# APM32L07x register map
File version: 1.0
CPU: CM0+ r0p0, little endian, MPU, no FPU, 4 interrupt priority bits
Registers are 32-bit, read-write, reset 0x0 unless marked. A register's access mark holds for its fields unless they carry their own. Offsets are from the block's base; [hi:lo] are bit positions; 'fields as' and 'values as' point back to an identical list.

## RCM — Reset and clock control
Base 0x40021000
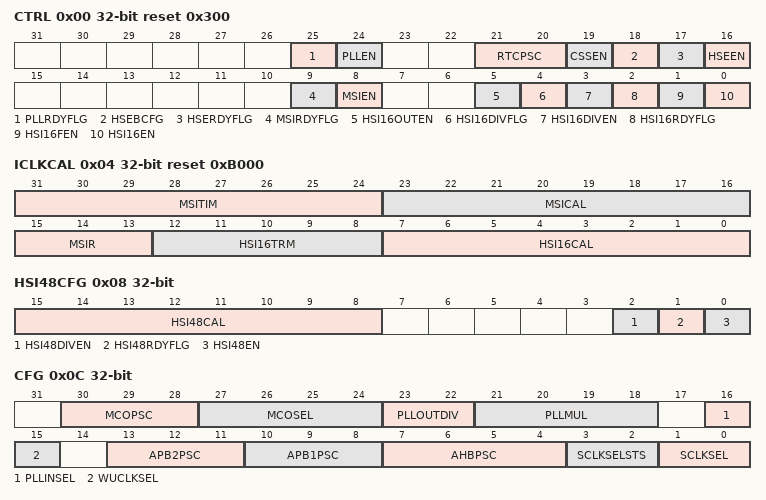
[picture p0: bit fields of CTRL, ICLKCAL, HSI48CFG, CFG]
0x00 CTRL access per field reset 0x300 — Clock control register
  [25] PLLRDYFLG ro — PLL Clock Ready Flag
  [24] PLLEN rw — PLL Enable
  [21:20] RTCPSC rw — RTC Clock Prescaler Factor Configure
  [19] CSSEN rw — Clock Security System Enable
  [18] HSEBCFG rw — High Speed External Clock Bypass Configure
  [17] HSERDYFLG ro — High Speed External Clock Ready Flag
  [16] HSEEN rw — High Speed External Clock Enable
  [9] MSIRDYFLG ro — MSICLK Ready Flag
  [8] MSIEN rw — Multispeed Internal Clock Enable
  [5] HSI16OUTEN rw — HSICLK16 Output Enable
  [4] HSI16DIVFLG ro — 16MHz HSI Divider by 4 Flag
  [3] HSI16DIVEN rw — 16MHz HSI Divider by 4 Enable
  [2] HSI16RDYFLG ro — 16MHz High Speed External Clock Ready Flag
  [1] HSI16FEN rw — 16MHz High Speed Internal Clock Force Enable
  [0] HSI16EN rw — 16MHz High Speed Internal Clock Enable
0x04 ICLKCAL access per field reset 0xB000 — Internal clock sources calibration register
  [31:24] MSITIM rw — MSICLK Trim
  [23:16] MSICAL ro — MSICLK Calibrate
  [15:13] MSIR rw — MSICLK Frequency Range
  [12:8] HSI16TRM rw — HSICLK16 Trim
  [7:0] HSI16CAL ro — HSICLK16 Calibrate
0x08 HSI48CFG access per field — Clock recovery RC register
  [15:8] HSI48CAL ro — HSICLK48 Calibrate
  [2] HSI48DIVEN rw — 48MHz HSI Divider by 6 Enable
  [1] HSI48RDYFLG ro — 48MHz High Speed External Clock Ready Flag
  [0] HSI48EN rw — HSICLK48 Enable
0x0C CFG access per field — Clock configuration register
  [30:28] MCOPSC rw — MCO Clock Output Prescaler Factor Configure
  [27:24] MCOSEL rw — MCO Clock Output Select
  [23:22] PLLOUTDIV rw — PLL Output Clock Divider Factor Configure
  [21:18] PLLMUL rw — PLL Multiplication Factor Configure
  [16] PLLINSEL rw — PLL Input Clock Select
  [15] WUCLKSEL rw — Wake up from STOP Clock Select
  [13:11] APB2PSC rw — APB2 Clock Prescaler Factor Configure
  [10:8] APB1PSC rw — APB1 Clock Prescaler Factor Configure
  [7:4] AHBPSC rw — AHB Clock Prescaler Factor Configure
  [3:2] SCLKSELSTS ro — System Clock Switch Status
  [1:0] SCLKSEL rw — System Clock Source Select
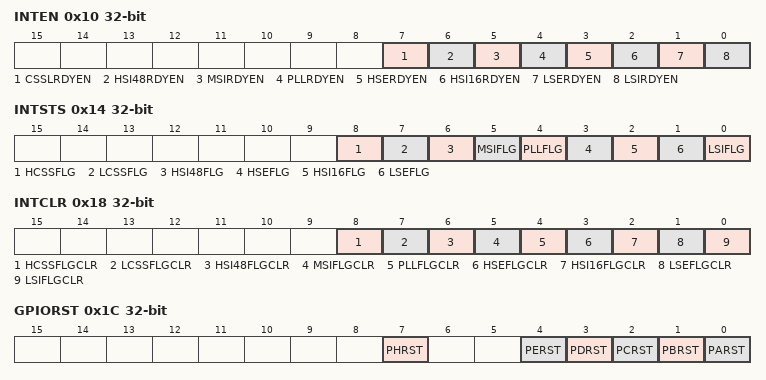
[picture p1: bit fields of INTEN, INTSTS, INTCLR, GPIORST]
0x10 INTEN — Clock interrupt enable register
  [7] CSSLRDYEN — Clock on LSE Security System Interrupt
  [6] HSI48RDYEN — HSICLK48 Ready Interrupt Enable
  [5] MSIRDYEN — MSICLK Ready Interrupt Enable
  [4] PLLRDYEN — PLLCLK Ready Interrupt Enable
  [3] HSERDYEN — HSECLK Ready Interrupt Enable
  [2] HSI16RDYEN — HSICLK16 Ready Interrupt Enable
  [1] LSERDYEN — LSECLK Ready Interrupt Enable
  [0] LSIRDYEN — LSICLK Ready Interrupt Enable
0x14 INTSTS ro — Clock interrupt flag register
  [8] HCSSFLG — HSE Clock Security System Interrupt Flag
  [7] LCSSFLG — LSE Clock Security System Interrupt Flag
  [6] HSI48FLG — HSICLK48 Ready Interrupt Flag
  [5] MSIFLG — MSICLK Ready Interrupt Flag
  [4] PLLFLG — PLLCLK Ready Interrupt Flag
  [3] HSEFLG — HSECLK Ready Interrupt Flag
  [2] HSI16FLG — HSICLK16 Ready Interrupt Flag
  [1] LSEFLG — LSECLK Ready Interrupt Flag
  [0] LSIFLG — LSICLK Ready Interrupt Flag
0x18 INTCLR wo — Clock interrupt clear register
  [8] HCSSFLGCLR — HSE Clock Security System Interrupt Flag Clear
  [7] LCSSFLGCLR — LSE Clock Security System Interrupt Flag Clear
  [6] HSI48FLGCLR — HSICLK48 Ready Interrupt Flag Clear
  [5] MSIFLGCLR — MSICLK Ready Interrupt Flag Clear
  [4] PLLFLGCLR — PLLCLK Ready Interrupt Flag Clear
  [3] HSEFLGCLR — HSECLK Ready Interrupt Flag Clear
  [2] HSI16FLGCLR — HSICLK16 Ready Interrupt Flag Clear
  [1] LSEFLGCLR — LSECLK Ready Interrupt Flag Clear
  [0] LSIFLGCLR — LSICLK Ready Interrupt Flag Clear
0x1C GPIORST — GPIO reset register
  [7] PHRST — GPIOH Reset
  [4] PERST — GPIOE Reset
  [3] PDRST — GPIOD Reset
  [2] PCRST — GPIOC Reset
  [1] PBRST — GPIOB Reset
  [0] PARST — GPIOA Reset
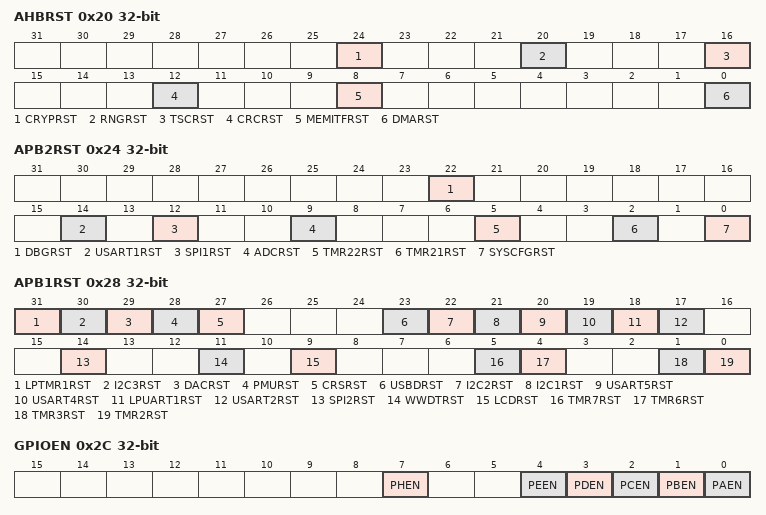
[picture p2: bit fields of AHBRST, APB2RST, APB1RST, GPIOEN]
0x20 AHBRST — AHB peripheral reset register
  [24] CRYPRST — Cryptographic Module Reset
  [20] RNGRST — RNG Reset
  [16] TSCRST — Touch Sensing Controller Module Reset
  [12] CRCRST — CRC Reset
  [8] MEMITFRST — Memory Interface Reset
  [0] DMARST — DMA Reset
0x24 APB2RST — APB2 peripheral reset register
  [22] DBGRST — DBG Reset
  [14] USART1RST — USART1 Reset
  [12] SPI1RST — SPI1 Reset
  [9] ADCRST — ADC Reset
  [5] TMR22RST — TMR22 Reset
  [2] TMR21RST — TMR21 Reset
  [0] SYSCFGRST — SYSCFG Reset
0x28 APB1RST — APB1 peripheral reset register
  [31] LPTMR1RST — LPTMR1 Reset
  [30] I2C3RST — I2C3 Reset
  [29] DACRST — DAC Reset
  [28] PMURST — PMU Reset
  [27] CRSRST — CRS Reset
  [23] USBDRST — USBD Reset
  [22] I2C2RST — I2C2 Reset
  [21] I2C1RST — I2C1 Reset
  [20] USART5RST — USART5 Reset
  [19] USART4RST — USART4 Reset
  [18] LPUART1RST — LPUSART1 Reset
  [17] USART2RST — USART2 Reset
  [14] SPI2RST — SPI2 Reset
  [11] WWDTRST — WWDT Reset
  [9] LCDRST — LCD Reset
  [5] TMR7RST — TMR7 Reset
  [4] TMR6RST — TMR6 Reset
  [1] TMR3RST — TMR3 Reset
  [0] TMR2RST — Timer2 reset
0x2C GPIOEN — GPIO clock enable register
  [7] PHEN — GPIOH Clock Enable
  [4] PEEN — GPIOE Clock Enable
  [3] PDEN — GPIOD Clock Enable
  [2] PCEN — GPIOC Clock Enable
  [1] PBEN — GPIOB Clock Enable
  [0] PAEN — GPIOA Clock Enable
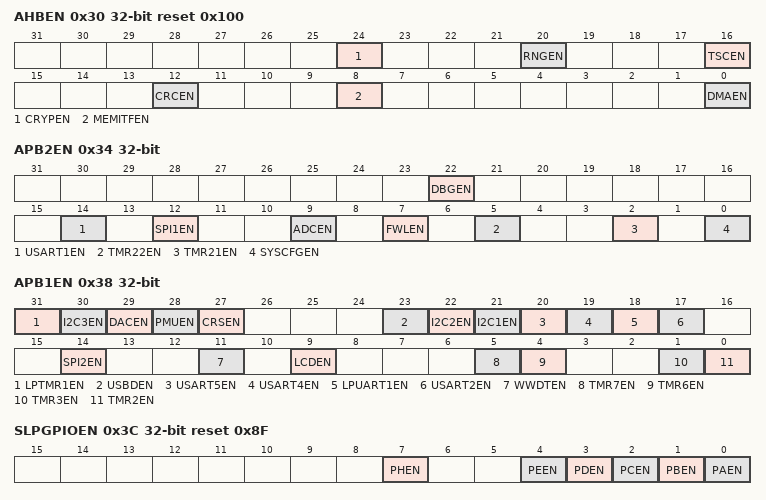
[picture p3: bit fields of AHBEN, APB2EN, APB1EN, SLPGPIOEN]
0x30 AHBEN reset 0x100 — AHB peripheral clock enable register
  [24] CRYPEN — Cryptographic Module Clock Enable
  [20] RNGEN — RNG Clock Enable
  [16] TSCEN — Touch Sensing Controller Module Clock Enable
  [12] CRCEN — CRC Clock Enable
  [8] MEMITFEN — Memory Interface Clock Enable
  [0] DMAEN — DMA Clock Enable
0x34 APB2EN — APB2 peripheral clock enable register
  [22] DBGEN — DBG Clock Enable
  [14] USART1EN — USART1 Clock Enable
  [12] SPI1EN — SPI1 Clock Enable
  [9] ADCEN — ADC Clock Enable
  [7] FWLEN — Firewall Clock Enable
  [5] TMR22EN — TMR22 Clock Enable
  [2] TMR21EN — TMR21 Clock Enable
  [0] SYSCFGEN — SYSCFG Clock Enable
0x38 APB1EN — APB1 peripheral clock enable register
  [31] LPTMR1EN — LPTMR1 Clock Enable
  [30] I2C3EN — I2C3 Clock Enable
  [29] DACEN — DAC Clock Enable
  [28] PMUEN — PMU Clock Enable
  [27] CRSEN — CRS Clock Enable
  [23] USBDEN — USBD Clock Enable
  [22] I2C2EN — I2C2 Clock Enable
  [21] I2C1EN — I2C1 Clock Enable
  [20] USART5EN — USART5 Clock Enable
  [19] USART4EN — USART4 Clock Enable
  [18] LPUART1EN — LPUSART1 Clock Enable
  [17] USART2EN — USART2 Clock Enable
  [14] SPI2EN — SPI2 Clock Enable
  [11] WWDTEN — WWDT Clock Enable
  [9] LCDEN — LCD Clock Enable
  [5] TMR7EN — TMR7 Clock Enable
  [4] TMR6EN — TMR6 Clock Enable
  [1] TMR3EN — TMR3 Clock Enable
  [0] TMR2EN — TMR2 Clock Enable
0x3C SLPGPIOEN reset 0x8F — GPIO clock enable in sleep mode register
  fields as GPIOEN
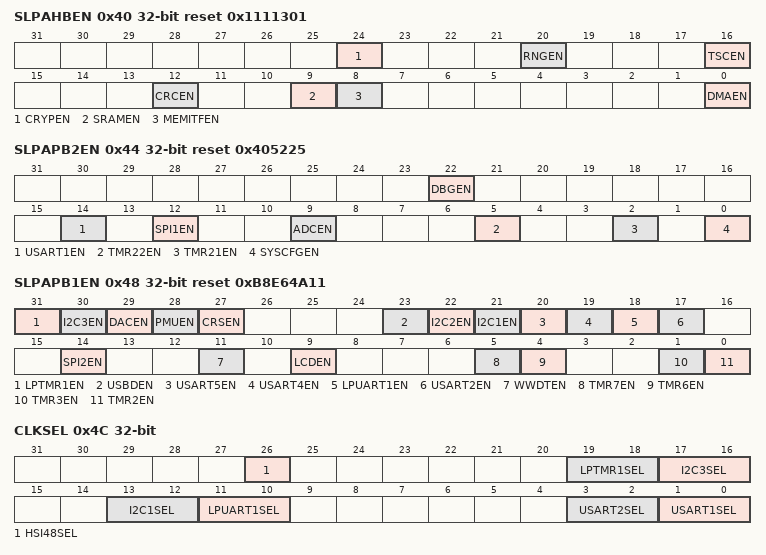
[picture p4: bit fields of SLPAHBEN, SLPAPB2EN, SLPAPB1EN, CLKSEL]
0x40 SLPAHBEN reset 0x1111301 — AHB peripheral clock enable in sleep mode register
  [24] CRYPEN — Cryptographic Module Clock Enable
  [20] RNGEN — RNG Clock Enable
  [16] TSCEN — Touch Sensing Controller Module Clock Enable
  [12] CRCEN — CRC Clock Enable
  [9] SRAMEN — SRAM Clock Enable
  [8] MEMITFEN — Memory Interface Clock Enable
  [0] DMAEN — DMA Clock Enable
0x44 SLPAPB2EN reset 0x405225 — APB2 peripheral clock enable in sleep mode register
  [22] DBGEN — DBG Clock Enable
  [14] USART1EN — USART1 Clock Enable
  [12] SPI1EN — SPI1 Clock Enable
  [9] ADCEN — ADC Clock Enable
  [5] TMR22EN — TMR22 Clock Enable
  [2] TMR21EN — TMR21 Clock Enable
  [0] SYSCFGEN — SYSCFG Clock Enable
0x48 SLPAPB1EN reset 0xB8E64A11 — APB1 peripheral clock enable in sleep mode register
  fields as APB1EN
0x4C CLKSEL — Clock configuration register
  [26] HSI48SEL — HSICLK48 Clock Source Select
  [19:18] LPTMR1SEL — LPTMR1 Clock Source Select
  [17:16] I2C3SEL — I2C3 Clock Source Select
  [13:12] I2C1SEL — I2C1 Clock Source Select
  [11:10] LPUART1SEL — LPUSART1 Clock Source Select
  [3:2] USART2SEL — USART2 Clock Source Select
  [1:0] USART1SEL — USART1 Clock Source Select
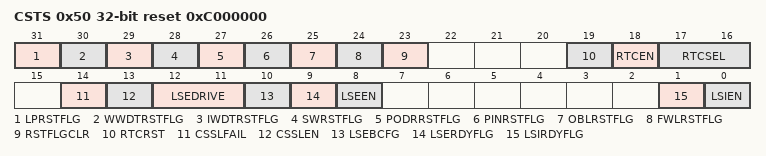
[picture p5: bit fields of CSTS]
0x50 CSTS access per field reset 0xC000000 — Control and status register
  [31] LPRSTFLG ro — Low Power Reset Flag
  [30] WWDTRSTFLG ro — Window Watchdog Reset Flag
  [29] IWDTRSTFLG ro — Independent Watchdog Reset Flag
  [28] SWRSTFLG ro — Software Reset Flag
  [27] PODRRSTFLG ro — POR/PDR Reset Flag
  [26] PINRSTFLG ro — Pin Reset Flag
  [25] OBLRSTFLG ro — Option Byte Loading Reset Flag
  [24] FWLRSTFLG ro — Firewall Reset Flag
  [23] RSTFLGCLR rw — Reset Flag Clear
  [19] RTCRST rw — RTC Reset
  [18] RTCEN rw — RTC Clock Enable
  [17:16] RTCSEL rw — RTC Clock Source Select
  [14] CSSLFAIL ro — CSS on LSECLK Detecte Failure Flag
  [13] CSSLEN rw — CSS on LSECLK Enable
  [12:11] LSEDRIVE rw — LSE Oscillator Driving Capability
  [10] LSEBCFG rw — Low-Speed External Clock Bypass Configure
  [9] LSERDYFLG ro — Low-Speed External Oscillator Ready Flag
  [8] LSEEN rw — Low-Speed External Oscillator Enable
  [1] LSIRDYFLG ro — Low-Speed Internal Oscillator Ready Flag
  [0] LSIEN rw — Low-Speed Internal Oscillator Enable
